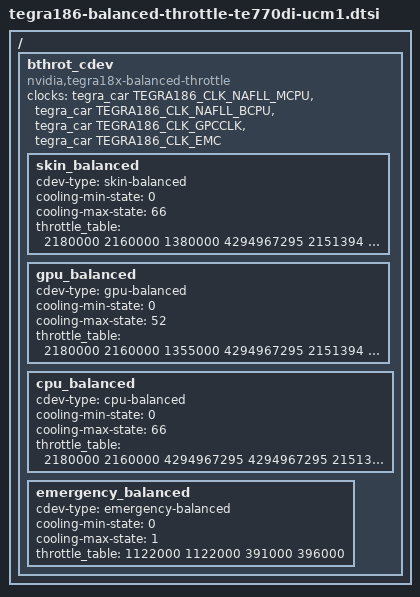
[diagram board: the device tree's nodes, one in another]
/*
 * arch/arm64/boot/dts/tegra186-platforms/tegra186-balanced-throttle-te770di-ucm1.dtsi
 *
 * Copyright (c) 2015-2016, NVIDIA CORPORATION.  All rights reserved.
 *
 * This program is free software; you can redistribute it and/or modify
 * it under the terms of the GNU General Public License as published by
 * the Free Software Foundation; version 2 of the License.
 *
 * This program is distributed in the hope that it will be useful, but WITHOUT
 * ANY WARRANTY; without even the implied warranty of MERCHANTABILITY or
 * FITNESS FOR A PARTICULAR PURPOSE.  See the GNU General Public License for
 * more details.
 *
 * You should have received a copy of the GNU General Public License along
 * with this program; if not, write to the Free Software Foundation, Inc.,
 * 51 Franklin Street, Fifth Floor, Boston, MA  02110-1301, USA.
 *
 */

/{
	bthrot_cdev {
		compatible = "nvidia,tegra18x-balanced-throttle";
		clocks = <&tegra_car TEGRA186_CLK_NAFLL_MCPU>,
				 <&tegra_car TEGRA186_CLK_NAFLL_BCPU>,
				 <&tegra_car TEGRA186_CLK_GPCCLK>,
				 <&tegra_car TEGRA186_CLK_EMC>;
		clock-names = "mcpu", "bcpu", "gpu", "emc";

		skin_balanced {
			cdev-type = "skin-balanced";
			cooling-min-state = <0>;
			cooling-max-state = <66>;
			#cooling-cells = <2>;
			throttle_table = <
				2180000	2160000	1380000	4294967295
				2151394	2131702	1362069	4294967295
				2122788	2103403	1344138	4294967295
				2094182	2075105	1326208	4294967295
				2065575	2046806	1308277	4294967295
				2036969	2018508	1290346	4294967295
				2008363	1990209	1272415	4294967295
				1979757	1961911	1254485	4294967295
				1951151	1933612	1236554	4294967295
				1922545	1905314	1218623	4294967295
				1893938	1877015	1200692	4294967295
				1865332	1848717	1182762	4294967295
				1836726	1820418	1164831	4294967295
				1808120	1792120	1146900	4294967295
				1779514	1763822	1128969	4294967295
				1750908	1735523	1111038	4294967295
				1722302	1707225	1093108	4294967295
				1693695	1678926	1075177	4294967295
				1665089	1650628	1057246	4294967295
				1636483	1622329	1039315	4294967295
				1607877	1594031	1021385	4294967295
				1579271	1565732	1003454	4294967295
				1550665	1537434	985523	4294967295
				1522058	1509135	967592	4294967295
				1493452	1480837	949662	4294967295
				1464846	1452538	931731	4294967295
				1436240	1424240	913800	4294967295
				1407634	1395942	895869	4294967295
				1379028	1367643	877938	4294967295
				1350422	1339345	860008	4294967295
				1321815	1311046	842077	4294967295
				1293209	1282748	824146	4294967295
				1264603	1254449	806215	4294967295
				1235997	1226151	788285	4294967295
				1207391	1197852	770354	4294967295
				1178785	1169554	752423	4294967295
				1150178	1141255	734492	4294967295
				1121572	1112957	716562	4294967295
				1092966	1084658	698631	4294967295
				1064360	1056360	680700	4294967295
				1035754	1028062	662769	4294967295
				1007148	999763	644838	4294967295
				978542	971465	626908	4294967295
				949935	943166	608977	4294967295
				921329	914868	591046	4294967295
				892723	886569	573115	4294967295
				864117	858271	555185	4294967295
				835511	829972	537254	4294967295
				806905	801674	519323	4294967295
				778298	773375	501392	4294967295
				749692	745077	483462	4294967295
				721086	716778	465531	4294967295
				692480	688480	447600	4294967295
				663874	660182	429669	4294967295
				635268	631883	411738	4294967295
				606662	603585	393808	4294967295
				578055	575286	375877	4294967295
				549449	546988	357946	4294967295
				520843	518689	340015	4294967295
				492237	490391	322085	4294967295
				463631	462092	304154	4294967295
				435025	433794	286223	4294967295
				406418	405495	268292	4294967295
				377812	377197	250362	4294967295
				349206	348898	232431	4294967295
				320600	320600	214500	4294967295
			>;
		};
		gpu_balanced {
			cdev-type = "gpu-balanced";
			cooling-min-state = <0>;
			cooling-max-state = <52>;
			#cooling-cells = <2>;
			throttle_table = <
				2180000	2160000	1355000	4294967295
				2151394	2131702	1332637	4294967295
				2122788	2103403	1310275	4294967295
				2094182	2075105	1287912	4294967295
				2065575	2046806	1265549	4294967295
				2036969	2018508	1243186	4294967295
				2008363	1990209	1220824	4294967295
				1979757	1961911	1198461	4294967295
				1951151	1933612	1176098	4294967295
				1922545	1905314	1153735	4294967295
				1893938	1877015	1131373	4294967295
				1865332	1848717	1109010	4294967295
				1836726	1820418	1086647	4294967295
				1808120	1792120	1064284	4294967295
				1779514	1763822	1041922	4294967295
				1750908	1735523	1019559	4294967295
				1722302	1707225	997196	4294967295
				1693695	1678926	974833	4294967295
				1665089	1650628	952471	4294967295
				1636483	1622329	930108	4294967295
				1607877	1594031	907745	4294967295
				1579271	1565732	885382	4294967295
				1550665	1537434	863020	4294967295
				1522058	1509135	840657	4294967295
				1493452	1480837	818294	4294967295
				1464846	1452538	795931	4294967295
				1436240	1424240	773569	4294967295
				1407634	1395942	751206	4294967295
				1379028	1367643	728843	4294967295
				1350422	1339345	706480	4294967295
				1321815	1311046	684118	4294967295
				1293209	1282748	661755	4294967295
				1264603	1254449	639392	4294967295
				1235997	1226151	617029	4294967295
				1207391	1197852	594667	4294967295
				1178785	1169554	572304	4294967295
				1150178	1141255	549941	4294967295
				1121572	1112957	527578	4294967295
				1092966	1084658	505216	4294967295
				1064360	1056360	482853	4294967295
				1035754	1028062	460490	4294967295
				1007148	999763	438127	4294967295
				978542	971465	415765	4294967295
				949935	943166	393402	4294967295
				921329	914868	371039	4294967295
				892723	886569	348676	4294967295
				864117	858271	326314	4294967295
				835511	829972	303951	4294967295
				806905	801674	281588	4294967295
				778298	773375	259225	4294967295
				749692	745077	236863	4294967295
				721086	716778	214500	4294967295
			>;
		};
		cpu_balanced {
			cdev-type = "cpu-balanced";
			cooling-min-state = <0>;
			cooling-max-state = <66>;
			#cooling-cells = <2>;
			throttle_table = <
				2180000	2160000	4294967295	4294967295
				2151394	2131702	4294967295	4294967295
				2122788	2103403	4294967295	4294967295
				2094182	2075105	4294967295	4294967295
				2065575	2046806	4294967295	4294967295
				2036969	2018508	4294967295	4294967295
				2008363	1990209	4294967295	4294967295
				1979757	1961911	4294967295	4294967295
				1951151	1933612	4294967295	4294967295
				1922545	1905314	4294967295	4294967295
				1893938	1877015	1430000	4294967295
				1865332	1848717	1407900	4294967295
				1836726	1820418	1385800	4294967295
				1808120	1792120	1363700	4294967295
				1779514	1763822	1341600	4294967295
				1750908	1735523	1319500	4294967295
				1722302	1707225	1297400	4294967295
				1693695	1678926	1275300	4294967295
				1665089	1650628	1253200	4294967295
				1636483	1622329	1231100	4294967295
				1607877	1594031	1209000	4294967295
				1579271	1565732	1186900	4294967295
				1550665	1537434	1164800	4294967295
				1522058	1509135	1142700	4294967295
				1493452	1480837	1120600	4294967295
				1464846	1452538	1098500	4294967295
				1436240	1424240	1076400	4294967295
				1407634	1395942	1054300	4294967295
				1379028	1367643	1032200	4294967295
				1350422	1339345	1010100	4294967295
				1321815	1311046	988000	4294967295
				1293209	1282748	965900	4294967295
				1264603	1254449	943800	4294967295
				1235997	1226151	921700	4294967295
				1207391	1197852	899600	4294967295
				1178785	1169554	877500	4294967295
				1150178	1141255	855400	4294967295
				1121572	1112957	833300	4294967295
				1092966	1084658	811200	4294967295
				1064360	1056360	789100	4294967295
				1035754	1028062	767000	4294967295
				1007148	999763	744900	4294967295
				978542	971465	722800	4294967295
				949935	943166	700700	4294967295
				921329	914868	678600	4294967295
				892723	886569	656500	4294967295
				864117	858271	634400	4294967295
				835511	829972	612300	4294967295
				806905	801674	590200	4294967295
				778298	773375	568100	4294967295
				749692	745077	546000	4294967295
				721086	716778	523900	4294967295
				692480	688480	501800	4294967295
				663874	660182	479700	4294967295
				635268	631883	457600	4294967295
				606662	603585	435500	4294967295
				578055	575286	413400	4294967295
				549449	546988	391300	4294967295
				520843	518689	369200	4294967295
				492237	490391	347100	4294967295
				463631	462092	325000	4294967295
				435025	433794	302900	4294967295
				406418	405495	280800	4294967295
				377812	377197	258700	4294967295
				349206	348898	236600	4294967295
				320600	320600	214500	4294967295
			>;
		};
		emergency_balanced {
			cdev-type = "emergency-balanced";
			cooling-min-state = <0>;
			cooling-max-state = <1>;
			#cooling-cells = <2>;
			throttle_table = <
				1122000	1122000	391000	396000
			>;
		};
	};
};
